# AE1C1F4051920PH0_CM55_HE_View register map
Vendor: Alif Semiconductor; Series: E1; File version: 1.0
CPU: CM55 r1p0, selectable endian, MPU, FPU, double-precision FPU, DSP, VTOR, 8 interrupt priority bits, 1 SAU regions
Registers are 32-bit, read-write, reset 0x0 unless marked. A register's access mark holds for its fields unless they carry their own. Offsets are from the block's base; [hi:lo] are bit positions; lines under a group give offsets from that group; {n}, {i} and the like mark numbered series.

## REFCLK_CNTRead
Base 0x1A210000
Same registers: S32K_CNTRead 0x1A410000
0x00 CNTCVL ro reset not defined — Read-only Version of CNTCVL Register
  [31:0] COUNTVALUE_LO — Read-only version of CNTCVL register.
0x04 CNTCVH ro reset not defined — Read-only Version of CNTCVH Register
  [31:0] COUNTVALUE_HI — Read-only version of CNTCVH register

## CGU
Base 0x1A602000
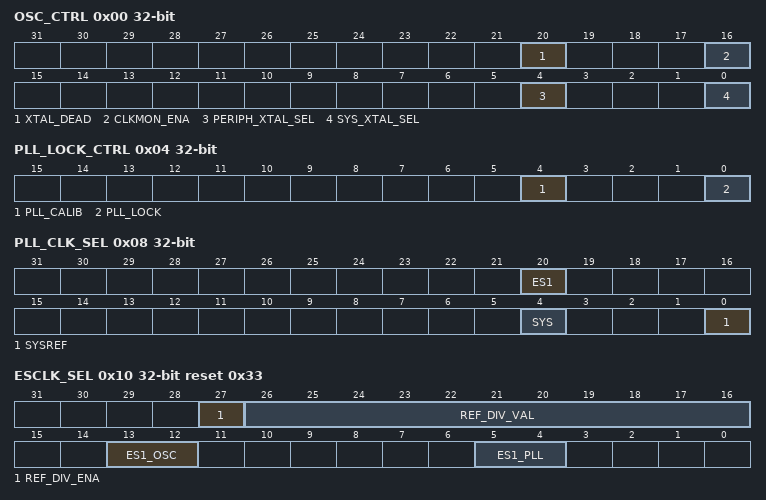
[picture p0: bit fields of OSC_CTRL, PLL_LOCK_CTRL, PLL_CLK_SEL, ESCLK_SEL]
0x00 OSC_CTRL — Oscillator Control Register
  [20] XTAL_DEAD ro — 38.4 MHz crystal-oscillator clock monitor status
    0=No crystal clock dead found; 1=Crystal clock dead detected
  [16] CLKMON_ENA — Enable 38.4 MHz crystal-oscillator clock monitor
    0=Disable clock monitor; 1=Enable clock monitor
  [4] PERIPH_XTAL_SEL — Select oscillator clock source for HFOSC_CLK
    0=Select 38.4 MHz (76.8 MHz / 2) ring-oscillator clock; 1=Select 38.4 MHz crystal-oscillator clock
  [0] SYS_XTAL_SEL — Select oscillator clock source for SYSPLL_CLK and SYST_REFCLK
    0=Select 76.8 MHz ring-oscillator clock; 1=Select 38.4 MHz crystal-oscillator clock
0x04 PLL_LOCK_CTRL — PLL Lock Control Register
  [4] PLL_CALIB ro — PLL calibration status
    0=PLL not in calibration; 1=PLL in calibration
  [0] PLL_LOCK — PLL lock control
    0=PLL not locked; 1=PLL locked
0x08 PLL_CLK_SEL — PLL Clock Select Register
  [20] ES1 — Select the source for RTSS_HE_CLK
    0=Select a value specified by the ESCLK_SEL[ES1_OSC] field; 1=Select a value specified by the ESCLK_SEL[ES1_PLL] field
  [4] SYS — Select the source for SYSPLL_CLK
    0=Select oscillator clock source; 1=Select PLL clock source
  [0] SYSREF — Select the source for SYST_REFCLK
    0=Select oscillator clock source; 1=Select PLL clock source
0x10 ESCLK_SEL reset 0x33 (reset mask 0x3FFF333) — Clock Select Register for M55-HE
  [27] REF_DIV_ENA — SYST_REFCLK divider enable
    0=Divider disabled. SYST_REFCLK is active and not divided.; 1=Divider enabled. SYST_REFCLK is active and divided by value specified in the ESCLK_SEL[REF_DIV_VAL] field.
  [26:16] REF_DIV_VAL — SYST_REFCLK divider values All other values: Reserved.
    0=Clock divided by 1; 2=Clock divided by 2; 4=Clock divided by 4; 8=Clock divided by 8; 16=Clock divided by 16; 32=Clock divided by 32; 64=Clock divided by 64; 128=Clock divided by 128; 0x100=Clock divided by 256; 0x200=Clock divided by 512; 0x400=Clock divided by 1024
  [13:12] ES1_OSC — Select oscillator clock frequency for RTSS_HE_CLK
    0=Select 76.8 MHz ring-oscillator clock; 1=Select 38.4 MHz ring-oscillator clock; 2=Select 76.8 MHz crystal-oscillator clock; 3=Select 38.4 MHz crystal-oscillator clock
  [5:4] ES1_PLL — Select PLL clock frequency for RTSS_HE_CLK
    0=Select 60 MHz PLL clock; 1=Select 80 MHz PLL clock; 2=Select 120 MHz PLL clock; 3=Select 160 MHz PLL clock
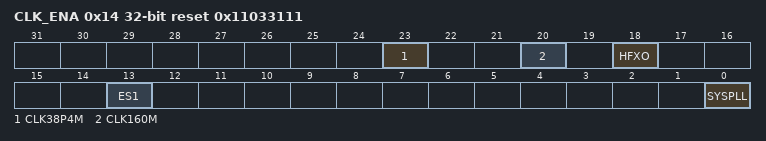
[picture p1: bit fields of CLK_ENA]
0x14 CLK_ENA reset 0x11033111 — Clock Enable Register
  [all] fields
    0=Disable clock; 1=Enable clock
  [23] CLK38P4M — Enable HFOSC_CLK
  [20] CLK160M — Enable PERIPH_CLK
  [18] HFXO — Enable clock to the HFXO_OUT pin
  [13] ES1 — Enable RTSS_HE_CLK
  [0] SYSPLL — Enable SYSPLL_CLK
0x20 CGU_IRQ ro — CGU Interrupt Status Register
  [0] XTAL_DEAD read-clears — 38.4 MHz crystal-oscillator dead. Active high, read to clear. Note: The XTAL_DEAD interrupt is mapped to the Secure Enclave.

## PINMUX
Base 0x1A603000
{0x0+0x20*i} PINMUX_CFG[{i}] (i=0..8) group
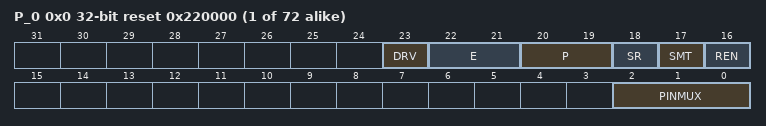
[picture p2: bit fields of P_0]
  {0x0+4j} P_{j} reset 0x220000 (j=0..7) — Control Register for Port n, Pin {j}
    [23] DRV — Driver type
      0=Push-pull; 1=Open drain
    [22:21] E — Output drive strength NOTE: Reset value is 0x3 (12 mA) for registers P0_0, P0_1, P0_7, P1_0, P1_1, P1_2, P2_2
      0=2 mA; 1=4 mA; 2=8 mA; 3=12 mA
    [20:19] P — Driver disabled state control
      0=High-Z; 1=Pull-up; 2=Pull-down; 3=Bus keeper
    [18] SR — Slew rate
      0=Slow; 1=Fast
    [17] SMT — Schmitt trigger (hysteresis) enable
      0=No hysteresis; 1=Hysteresis enabled
    [16] REN — Receiver enable NOTE: Reset value is 0x1 for registers P0_0, P0_1, P0_7, P1_0, P1_1, P1_2, P2_2
      0=Receiver disabled, pin reads return 0; 1=Receiver enabled
    [2:0] PINMUX — Pin multiplexing control field 0x1-0xN: Selects other peripherals as shown in table Pin Function Multiplexing of the device series-specific Datasheet. Un-mapped: Select GPIOn_{j} NOTE: Reset value is 0x1 for registers P0_0, P0_1, P0_7, P1_0, P1_1, P1_2, P2_2
      0=Selects GPIOn_{j} signal from GPIOn peripheral
